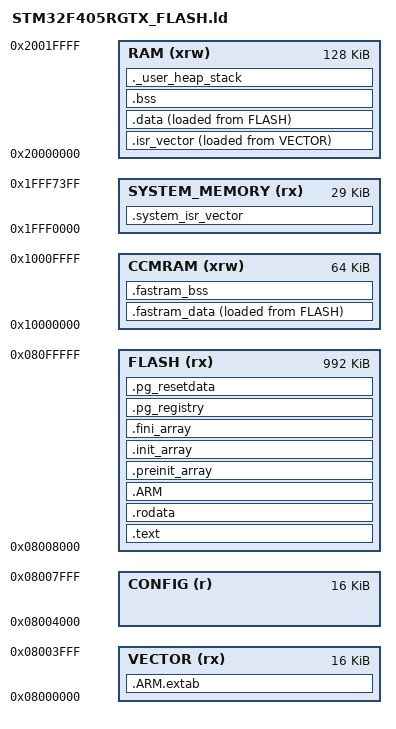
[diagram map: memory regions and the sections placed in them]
/**
 ******************************************************************************
 * @file      LinkerScript.ld
 * @author    Auto-generated by STM32CubeIDE
 * @brief     Linker script for STM32F405RGTx Device from STM32F4 series
 *                      1024Kbytes FLASH
 *                      64Kbytes CCMRAM
 *                      128Kbytes RAM
 *
 *            Set heap size, stack size and stack location according
 *            to application requirements.
 *
 *            Set memory bank area and size if external memory is used
 ******************************************************************************
 * @attention
 *
 * <h2><center>&copy; Copyright (c) 2020 STMicroelectronics.
 * All rights reserved.</center></h2>
 *
 * This software component is licensed by ST under BSD 3-Clause license,
 * the "License"; You may not use this file except in compliance with the
 * License. You may obtain a copy of the License at:
 *                        opensource.org/licenses/BSD-3-Clause
 *
 ******************************************************************************
 */

/* Entry Point */
ENTRY(Reset_Handler)

/* Highest address of the user mode stack */
_estack = ORIGIN(RAM) + LENGTH(RAM);	/* end of "RAM" Ram type memory */

/* Base address where the config is stored. */
__config_start = ORIGIN(CONFIG);
__config_end = ORIGIN(CONFIG) + LENGTH(CONFIG);

_Min_Heap_Size = 0x200;	/* required amount of heap  */
_Min_Stack_Size = 0x400;	/* required amount of stack */

/* Memories definition */
MEMORY
{
  CCMRAM         (xrw)    : ORIGIN = 0x10000000,   LENGTH =    64K
  SYSTEM_MEMORY  (rx)     : ORIGIN = 0x1FFF0000,   LENGTH =    29K
  RAM            (xrw)    : ORIGIN = 0x20000000,   LENGTH =   128K
  VECTOR         (rx)     : ORIGIN = 0x08000000,   LENGTH =    16K
  CONFIG         (r)      : ORIGIN = 0x08004000,   LENGTH =    16K
  FLASH          (rx)     : ORIGIN = 0x08008000,   LENGTH =   992K
}

/* Sections */
SECTIONS
{
  _isr_vector_table_flash_base = LOADADDR(.isr_vector);
  PROVIDE (isr_vector_table_flash_base = _isr_vector_table_flash_base);
  /* The startup code into "FLASH" Rom type memory */
  .isr_vector :
  {
    . = ALIGN(4);
    PROVIDE (isr_vector_table_base = .);
    KEEP(*(.isr_vector)) /* Startup code */
    . = ALIGN(4);
    PROVIDE (isr_vector_table_end = .);
  } >RAM AT> VECTOR

  /* System memory (read-only bootloader) interrupt vector */
  .system_isr_vector (NOLOAD) :
  {
    . = ALIGN(4);
    PROVIDE (system_isr_vector_table_base = .);
    KEEP(*(.system_isr_vector)) /* Bootloader code */
    . = ALIGN(4);
  } >SYSTEM_MEMORY

  /* The program code and other data into "FLASH" Rom type memory */
  .text :
  {
    . = ALIGN(4);
    *(.text)           /* .text sections (code) */
    *(.text*)          /* .text* sections (code) */
    *(.glue_7)         /* glue arm to thumb code */
    *(.glue_7t)        /* glue thumb to arm code */
    *(.eh_frame)

    KEEP (*(.init))
    KEEP (*(.fini))

    . = ALIGN(4);
    _etext = .;        /* define a global symbols at end of code */
  } >FLASH

  /* Constant data into "FLASH" Rom type memory */
  .rodata :
  {
    . = ALIGN(4);
    *(.rodata)         /* .rodata sections (constants, strings, etc.) */
    *(.rodata*)        /* .rodata* sections (constants, strings, etc.) */
    . = ALIGN(4);
  } >FLASH

  .ARM.extab   : {
    . = ALIGN(4);
    *(.ARM.extab* .gnu.linkonce.armextab.*)
    . = ALIGN(4);
  } >VECTOR

  .ARM : {
    . = ALIGN(4);
    __exidx_start = .;
    *(.ARM.exidx*)
    __exidx_end = .;
    . = ALIGN(4);
  } >FLASH

  .preinit_array     :
  {
    . = ALIGN(4);
    PROVIDE_HIDDEN (__preinit_array_start = .);
    KEEP (*(.preinit_array*))
    PROVIDE_HIDDEN (__preinit_array_end = .);
    . = ALIGN(4);
  } >FLASH

  .init_array :
  {
    . = ALIGN(4);
    PROVIDE_HIDDEN (__init_array_start = .);
    KEEP (*(SORT(.init_array.*)))
    KEEP (*(.init_array*))
    PROVIDE_HIDDEN (__init_array_end = .);
    . = ALIGN(4);
  } >FLASH

  .fini_array :
  {
    . = ALIGN(4);
    PROVIDE_HIDDEN (__fini_array_start = .);
    KEEP (*(.fini_array*))
    KEEP (*(SORT(.fini_array.*)))
    PROVIDE_HIDDEN (__fini_array_end = .);
    . = ALIGN(4);
  } >FLASH

  .pg_registry :
  {
    . = ALIGN(4);
    PROVIDE_HIDDEN (__pg_registry_start = .);
    KEEP(*(.pg_registry)) /* Parameter Gruop code */
    KEEP (*(SORT(.pg_registry.*)))
    . = ALIGN(4);
    PROVIDE_HIDDEN (__pg_registry_end = .);
  } >FLASH

  .pg_resetdata :
  {
    PROVIDE_HIDDEN (__pg_resetdata_start = .);
    KEEP (*(.pg_resetdata))
    PROVIDE_HIDDEN (__pg_resetdata_end = .);
  } >FLASH

  /* Used by the startup to initialize data */
  _sidata = LOADADDR(.data);

  /* Initialized data sections into "RAM" Ram type memory */
  .data :
  {
    . = ALIGN(4);
    _sdata = .;        /* create a global symbol at data start */
    *(.data)           /* .data sections */
    *(.data*)          /* .data* sections */

    . = ALIGN(4);
    _edata = .;        /* define a global symbol at data end */

  } >RAM AT> FLASH

  /* Uninitialized data section into "RAM" Ram type memory */
  . = ALIGN(4);
  .bss (NOLOAD) :
  {
    /* This is used by the startup in order to initialize the .bss section */
    _sbss = .;         /* define a global symbol at bss start */
    __bss_start__ = _sbss;
    *(.bss)
    *(SORT_BY_ALIGNMENT(.bss*))
    *(COMMON)

    . = ALIGN(4);
    _ebss = .;         /* define a global symbol at bss end */
    __bss_end__ = _ebss;
  } >RAM

    /* used during startup to initialized fastram_data */
  _sfastram_idata = LOADADDR(.fastram_data);

  /* Initialized FAST_DATA section for unsuspecting developers */
  .fastram_data :
  {
    . = ALIGN(4);
    _sfastram_data = .;        /* create a global symbol at data start */
    *(.fastram_data)           /* .data sections */
    *(.fastram_data*)          /* .data* sections */

    . = ALIGN(4);
    _efastram_data = .;        /* define a global symbol at data end */
  } >CCMRAM AT> FLASH

  . = ALIGN(4);
  .fastram_bss (NOLOAD) :
  {
    __fastram_bss_start__ = .;
    *(.fastram_bss)
    *(SORT_BY_ALIGNMENT(.fastram_bss*))
    . = ALIGN(4);
    __fastram_bss_end__ = .;
  } >CCMRAM

  /* User_heap_stack section, used to check that there is enough "RAM" Ram  type memory left */
  ._user_heap_stack :
  {
    . = ALIGN(8);
    PROVIDE ( end = . );
    PROVIDE ( _end = . );
    . = . + _Min_Heap_Size;
    . = . + _Min_Stack_Size;
    . = ALIGN(8);
  } >RAM

  /* Remove information from the compiler libraries */
  /DISCARD/ :
  {
    libc.a ( * )
    libm.a ( * )
    libgcc.a ( * )
  }

  .ARM.attributes 0 : { *(.ARM.attributes) }
}
